# ESP32S31_RADIO register map
Vendor: Espressif; Series: ESP32-S31; File version: 3.52
Registers are 32-bit, read-write, no defined reset value unless marked. A register's access mark holds for its fields unless they carry their own. Offsets are from the block's base; [hi:lo] are bit positions; {n}, {i} and the like mark numbered series.

## WIFI_MAC_TSF_TIMER — Four-entry TSF timer bank recovered from all complete target, wakeup and enable/disable leaves. Each entry consists of one control word followed by its 32-bit target. The public index is guarded to zero through three by the target and timer-enable leaves; the dedicated wakeup leaves do not contain their own range check.
Base 0x2010D87C
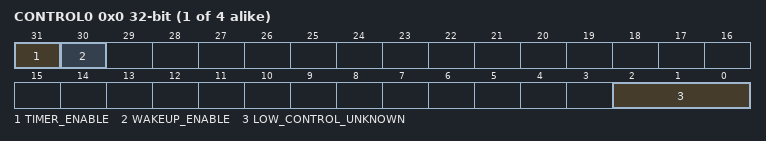
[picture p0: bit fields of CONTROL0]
{0x0+8i} CONTROL{i} (i=0..3) — Per-timer control word at 0x2010d87c + index*8. Complete target accessors replace and return the low three bits; the exact semantics of that field remain unknown. Dedicated leaves set or clear wakeup bit 30, while the timer enable/disable leaves set or clear bit 31.
  [31] TIMER_ENABLE — Set by hal_enable_tsf_timer and cleared by hal_disable_tsf_timer.
  [30] WAKEUP_ENABLE — Set by hal_enable_tsf_timer_wakeup and cleared by hal_disable_tsf_timer_wakeup.
  [2:0] LOW_CONTROL_UNKNOWN — Complete hal_tsf_timer_set_target replaces these bits from its third argument and hal_tsf_timer_get_target returns them through its second output pointer.
{0x4+8i} TARGET{i} (i=0..3) — Full 32-bit timer target written by hal_tsf_timer_set_target and returned through the first output pointer by hal_tsf_timer_get_target.
  [31:0] VALUE

## COEX_HW_TIMER — Five-entry coexistence timer bank. Complete libcoexist leaves address entry index as 0x2010f400 + index*0x10. The independent 46-event coex_core_timer_idx_get table returns only timer indices zero through four or 0xff for an invalid event.
Base 0x2010F400
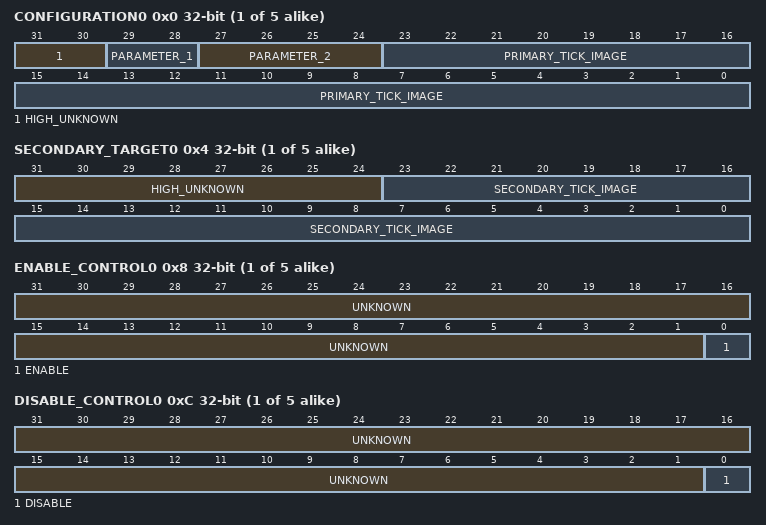
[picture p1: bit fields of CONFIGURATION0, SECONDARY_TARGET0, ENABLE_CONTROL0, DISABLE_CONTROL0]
{0x0+0x10*i} CONFIGURATION{i} (i=0..4) — Primary timer word. coex_hw_timer_set replaces both high nibbles and the low 24-bit tick image through separate fresh-read RMW operations. coex_hw_timer_force clears the low 24 bits; coex_hw_timer_unforce replaces them with 1000.
  [31:30] HIGH_UNKNOWN — Bits preserved by coex_hw_timer_set while PARAMETER_1 is replaced.
  [29:28] PARAMETER_1 — Low two bits of the second coex_hw_timer_set argument. Bits 31:30 are preserved by the complete vendor RMW.
  [27:24] PARAMETER_2 — Low nibble of the third coex_hw_timer_set argument.
  [23:0] PRIMARY_TICK_IMAGE — Low 24 bits returned by coex_hw_timer_tick_get for the first timer value. The exact counter epoch and units remain part of the reviewed timer conversion rather than the register geometry.
{0x4+0x10*i} SECONDARY_TARGET{i} (i=0..4) — Secondary timer word. coex_hw_timer_set preserves the high byte and replaces the low 24 bits with the converted fourth timer-value argument.
  [31:24] HIGH_UNKNOWN, [23:0] SECONDARY_TICK_IMAGE
{0x8+0x10*i} ENABLE_CONTROL{i} (i=0..4) — coex_hw_timer_enable sets bit zero here after clearing bit zero in the paired disable-control word. coex_hw_timer_disable performs the inverse transaction.
  [31:1] UNKNOWN, [0] ENABLE
{0xC+0x10*i} DISABLE_CONTROL{i} (i=0..4) — coex_hw_timer_disable sets bit zero here after clearing bit zero in the paired enable-control word. coex_hw_timer_enable performs the inverse transaction.
  [31:1] UNKNOWN, [0] DISABLE

## WIFI_MAC_COEX_RUNTIME — Runtime receive-beacon and individual-TWT COEX/PTI words recovered from five complete hal_coex.o leaves. Register addresses, masks and RMW order are exact; fields whose electrical meaning is not established retain UNKNOWN names.
Base 0x2010D89C
0x00 CLEAR_REQUEST — Complete hal_clear_rx_beacon_pti sets bit zero through a fresh-read RMW. Complete hal_clr_itwt_pti sets the input-selected bit through the same word; the accepted index domain and remaining bit identities are not inferred.
  [31:0] REQUESTS_UNKNOWN
0x04 RX_BEACON_TIME_HIGH — Complete hal_set_rx_beacon_time replaces the low byte from bits 15:8 of its second argument after updating WIFI_MAC_RTC_TIMER_UPDATE.RX_BEACON_TIME_LOW.
  [7:0] VALUE
0x08 ITWT_CONTROL — Complete hal_set_itwt_pti clears the low byte and then writes seqz(argument zero) into bit zero. The remaining low-byte semantics are unknown.
  [7:0] LOW_CONTROL_UNKNOWN
0x0C SHARED_RX_PTI — Shared receive PTI word updated from the second argument by complete hal_set_rx_beacon_pti and hal_set_itwt_pti. Both leaves preserve bits 31:4 and replace only bits 3:0.
  [3:0] PTI
0x10 RX_BEACON_PTI — Complete hal_set_rx_beacon_pti replaces bits 15:12 from the low nibble of its first argument.
  [15:12] PTI
